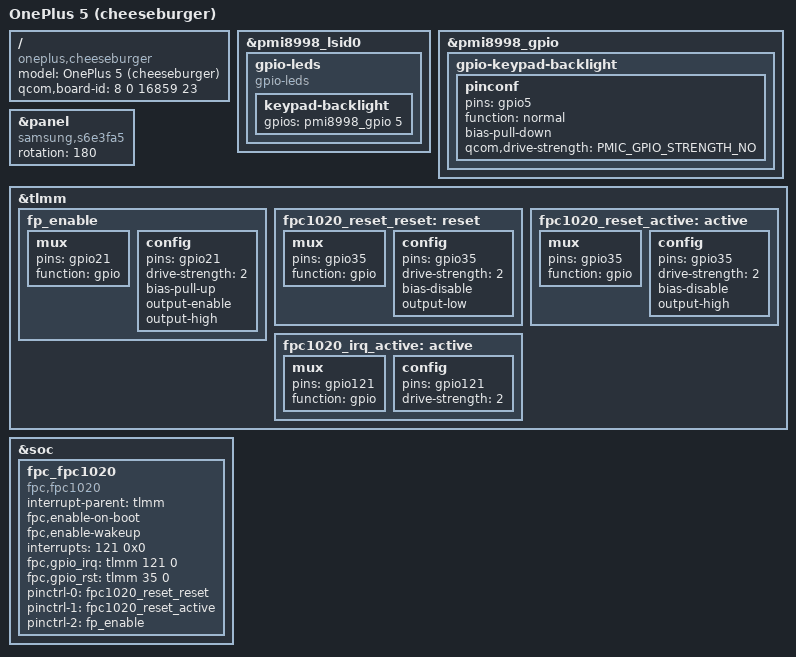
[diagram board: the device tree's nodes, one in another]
// SPDX-License-Identifier: GPL-2.0-only

/dts-v1/;

#include "msm8998-oneplus-common.dtsi"

/ {
	model = "OnePlus 5 (cheeseburger)";
	compatible = "oneplus,cheeseburger", "qcom,msm8998";
	/* Required for bootloader to select correct board */
	qcom,board-id = <8 0 16859 23>;
};

/* Capacitive keypad button backlight */
&pmi8998_lsid0 {
	gpio-leds {
		compatible = "gpio-leds";

		keypad-backlight {
			gpios = <&pmi8998_gpio 5 GPIO_ACTIVE_HIGH>;
			//label = "button-backlight"; // Expose brightness control in /sys/class/leds/button-backlight/
			//default-state = "on"; // Enable backlight for capacitive keys by default
		};
	};
};

&pmi8998_gpio {
	gpio-keypad-backlight {
		pinconf {
			pins = "gpio5";
			function = "normal";
			bias-pull-down;
			qcom,drive-strength = <PMIC_GPIO_STRENGTH_NO>;
		};
	};
};

/* Display */
&panel {
	compatible = "samsung,s6e3fa5";

	rotation = <180>; /* The panel is mounted upside down on the OnePlus 5 */
};

&tlmm {
	fp_enable: fp_enable {
		mux {
			pins = "gpio21";
			function = "gpio";
		};

		config {
			pins = "gpio21";
			drive-strength = <2>;
			bias-pull-up;
			output-enable;
			output-high;
		};
	};

	fpc1020_reset_reset: reset {
		mux {
			pins = "gpio35";
			function = "gpio";
		};

		config{
			pins = "gpio35";
			drive-strength = <2>;
			bias-disable;
			output-low;
		};
	};

	fpc1020_reset_active: active {
		mux {
			pins = "gpio35";
			function = "gpio";
		};

		config{
			pins = "gpio35";
			drive-strength = <2>;
			bias-disable;
			output-high;
		};
	};

	fpc1020_irq_active: active {
		mux {
			pins = "gpio121";
			function = "gpio";
		};

		config{
			pins = "gpio121";
			drive-strength = <2>;
		};
	};
};

&soc {
	/* Fingerprint */
	fpc_fpc1020 {
		compatible = "fpc,fpc1020";
		interrupt-parent = <&tlmm>;
		fpc,enable-on-boot;
		fpc,enable-wakeup;
		//vdd_ana = <&vreg_l12a_1p8>;
		interrupts = <121 0x0>;
		fpc,gpio_irq= <&tlmm 121 0>;
		fpc,gpio_rst = <&tlmm 35 0>;
		pinctrl-names = //     "fpc1020_irq_active",
			"fpc1020_reset_reset",
			"fpc1020_reset_active",
			"fp_enable";
		//pinctrl-0 = <&fpc1020_irq_active>;
		pinctrl-0 = <&fpc1020_reset_reset>;
		pinctrl-1 = <&fpc1020_reset_active>;
		pinctrl-2 = <&fp_enable>;
	};
};
